# D2522AA register map
Vendor: Dialog; Series: D2522AA; File version: 1.2
CPU: CM0 r1p0, little endian, MPU, FPU, 3 interrupt priority bits
Registers are 32-bit, read-write, reset 0x0 unless marked. A register's access mark holds for its fields unless they carry their own. Offsets are from the block's base; [hi:lo] are bit positions; <NAME> marks a mode.

## CRG_XTAL — CRG_XTAL registers
Base 0x50010000
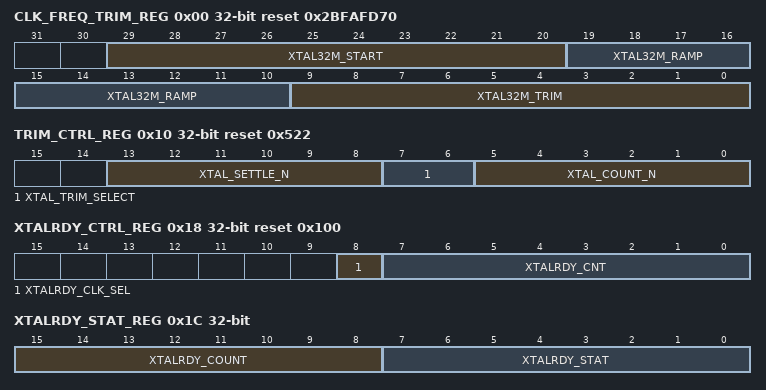
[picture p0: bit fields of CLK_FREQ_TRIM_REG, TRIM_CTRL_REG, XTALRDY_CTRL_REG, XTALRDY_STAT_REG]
0x00 CLK_FREQ_TRIM_REG reset 0x2BFAFD70 — Xtal frequency trimming register.
  [29:20] XTAL32M_START — Xtal frequency trimming register - START phase of startup 0x2BF = lowest frequency (high load capacitance) 0x000 = highest frequency (low load capacitance) Cload = 2.25p + 6.2p * XTAL32M_TRIM/0x2BF
  [19:10] XTAL32M_RAMP — Xtal frequency trimming register - RAMP phase of startup. 0x2BF = lowest frequency (high load capacitance) 0x000 = highest frequency (low load capacitance) Cload = 2.25p + 6.2p * XTAL32M_TRIM/0x2BF
  [9:0] XTAL32M_TRIM — Xtal frequency trimming register. 0x2BF = lowest frequency (high load capacitance) 0x000 = highest frequency (low load capacitance) Cload = 2.25p + 6.2p * XTAL32M_TRIM/0x2BF
0x0C XTAL32M_TRSTAT_REG — Read back value of current XTAL trimming
  [14:0] XTAL32M_TRSTAT ro — Reads value of the current XTAL trimming
0x10 TRIM_CTRL_REG reset 0x522 — Control trimming of the XTAL32M
  [13:8] XTAL_SETTLE_N — Designates that the XTAL can be safely used as the CPU clock. When XTAL_CLK_CNT reases this value, the signal XTAL_SETTLE_READY will be set
  [7:6] XTAL_TRIM_SELECT — Select which source controls the XTAL trimming 0b00: xtal counter. Starts XTAL32M_START_REG, after COUNT_N * 32 xtal pulses trim is changed to CLK_FREQ_TRIM_REG. 0b01: xtal OK filter. Starts with XTAL32_START_REG, when xtal is ramping is changed to CLK_FREQ_TRIM_REG 0b10: statically forced off. Only uses CLK_FREQ_TRIM_REG. 0b11: xtal OK filter, 2 stage. Starts with XTAL32_START_REG switches to XTAL16M_RAMP_REG when sw1='1', and switches to CLK_FREQ_TRIM_REG when sw2='1'.
  [5:0] XTAL_COUNT_N — Defines the number of XTAL cycles to be counted, before the xtal trimming is applied, in steps of 32. 0x01: 32 0x02: 64 0x3f:2016
0x18 XTALRDY_CTRL_REG reset 0x100 — Control register for XTALRDY IRQ
  [8] XTALRDY_CLK_SEL — XTALRDY IRQ timer clock selection: 0: 32KHz 1: 256kHz
  [7:0] XTALRDY_CNT — Number of 32kHz or 256kHz cycles between the crystal is enabled, and the XTALRDY_IRQ is fired. Frequency set by XTALRDY_CLK_SEL. 0x00: no interrupt
0x1C XTALRDY_STAT_REG — Difference between XTAL_OK and XTALRDY_IRQ in LP clock cycles
  [15:8] XTALRDY_COUNT ro — Current value of IRQ counter
  [7:0] XTALRDY_STAT ro — Value of IRQ counter when trimming is switched from RAMP to TRIM
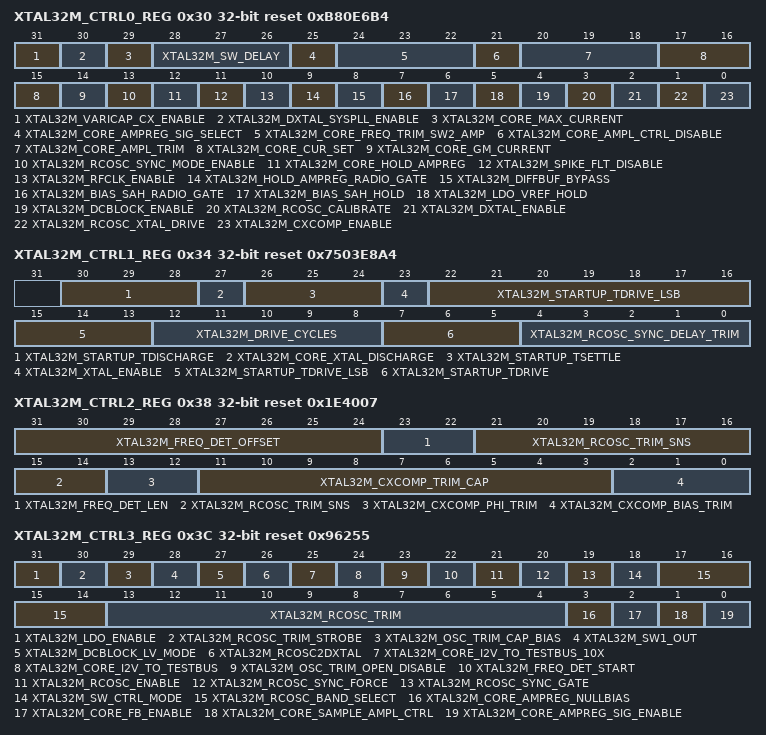
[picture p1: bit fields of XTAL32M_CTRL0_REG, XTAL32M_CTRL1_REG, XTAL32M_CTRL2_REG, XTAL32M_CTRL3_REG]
0x30 XTAL32M_CTRL0_REG reset 0xB80E6B4 (reset mask 0x7FFFFFFF) — Control register for XTAL32M
  [31] XTAL32M_VARICAP_CX_ENABLE — Enables shunt-cap compensation capacitance (OSF BOOST)
  [30] XTAL32M_DXTAL_SYSPLL_ENABLE — Enables DXTAL for the system PLL.
  [29] XTAL32M_CORE_MAX_CURRENT — Forces maximum current in output device.
  [28:26] XTAL32M_SW_DELAY — Set sw1 delay (sample output current comparator) and sw2 mask delay time. 0x0: 128 us 0x1: 64 us 0x2: 32 us 0x3: 16 us 0x4: 8 us 0x5: 4 us 0x6: 2 us 0x7: 1 us
  [25] XTAL32M_CORE_AMPREG_SIG_SELECT — 1: Select xtal_n for amplitude control. 0: Select xtal_p for amplitude control.
  [24:22] XTAL32M_CORE_FREQ_TRIM_SW2_AMP — Set threshold for amplitude control ok detection. 0x0: Highest current delta 0x6: Lowest current delta 0x7: off
  [21] XTAL32M_CORE_AMPL_CTRL_DISABLE — Disable amplitude-control block.
  [20:18] XTAL32M_CORE_AMPL_TRIM — Core amplitude trim setting. 0x0: min amplitude ... ... 0x5: max amplitude 0x6 & 0x7 are equal to 0x3.
  [17:15] XTAL32M_CORE_CUR_SET — Core current trim setting. 0x0: min current ... 0x3: default current ... 0x6 max amplitude 0x7 is equal to 0x3.
  [14] XTAL32M_CORE_GM_CURRENT — Enables biassing of the main oscillator output device
  [13] XTAL32M_RCOSC_SYNC_MODE_ENABLE — Enable synchronization of the crystal startup.
  [12] XTAL32M_CORE_HOLD_AMPREG — Put amplitude detector in HOLD mode.
  [11] XTAL32M_SPIKE_FLT_DISABLE — Disable DXTAL spike filter.
  [10] XTAL32M_RFCLK_ENABLE — If set, rfclk is allowed to be enabled
  [9] XTAL32M_HOLD_AMPREG_RADIO_GATE — Allow radio_enable to put amplitude detector in HOLD mode.
  [8] XTAL32M_DIFFBUF_BYPASS — Bypass comparator to use external input.
  [7] XTAL32M_BIAS_SAH_RADIO_GATE — Allow radio_enable to put the bias block in HOLD mode.
  [6] XTAL32M_BIAS_SAH_HOLD — Put the bias block in HOLD mode.
  [5] XTAL32M_LDO_VREF_HOLD — Put the LDO in HOLD mode.
  [4] XTAL32M_DCBLOCK_ENABLE — Eable dcblock circuit.
  [3] XTAL32M_RCOSC_CALIBRATE — Request an RC-oscillator calibration. If set, calibration will be started after xtal startup.
  [2] XTAL32M_DXTAL_ENABLE — Enable DXTAL - signal is gated by state-machine. Bit should always be set.
  [1] XTAL32M_RCOSC_XTAL_DRIVE — Enable drive of crystal by RCOSC, needed for fast startup
  [0] XTAL32M_CXCOMP_ENABLE — Enable the shunt-capacitance compensation amplifier circuit (OSF BOOST).
0x34 XTAL32M_CTRL1_REG reset 0x7503E8A4 — Control register for XTAL32M
  [30:28] XTAL32M_STARTUP_TDISCHARGE — Discharge time. 0x0: disable 0x1: 8 us 0x2: 4 us 0x3: 2 us 0x4: 1 us 0x5: 1/2 us 0x6: 1/8 us 0x7: 1/32 us
  [27] XTAL32M_CORE_XTAL_DISCHARGE — Software control mode: discharges the crystal.
  [26:24] XTAL32M_STARTUP_TSETTLE — Settle time. 0x0: 16 us 0x1: 8 us 0x2: 4 us 0x3: 2 us 0x4: 1 us 0x5: 1/2 us 0x6: 1/4 us 0x7: 1/8 us
  [23] XTAL32M_XTAL_ENABLE — Enable xtal (startup) or enable xtal block (software control mode) - testing only, to enable xtal, use PDC.
  [22:13] XTAL32M_STARTUP_TDRIVE_LSB — LSB part of the sequence drive time. From 0 to 32us with steps of 1/32us.
  [12:8] XTAL32M_DRIVE_CYCLES — Number of sequences to drive at startup.
  [7:5] XTAL32M_STARTUP_TDRIVE — Drive time of the sequence. 0x0: 32 us 0x1: 16 us 0x2: 8 us 0x3: 4 us 0x4: 2 us 0x5: 1 us 0x6: 1/2 us 0x7: 1/4 us
  [4:0] XTAL32M_RCOSC_SYNC_DELAY_TRIM — Synchronization mode delay trim..
0x38 XTAL32M_CTRL2_REG reset 0x1E4007 (reset mask 0x7FFFFFFF) — Control register for XTAL32M
  [31:24] XTAL32M_FREQ_DET_OFFSET — Add extra offset to the frequency-detector result to compensate for mismatch between actual startup and frequency-detector result.
  [23:22] XTAL32M_FREQ_DET_LEN — Length of frequency detection, used during calibration of the RC-oscillator. 0x0 :256us M=8k 0x1: 128us M=4k 0x2: 64us M=2k 0x3: 32us M=1k
  [21:14] XTAL32M_RCOSC_TRIM_SNS — Trim sensitivity used during calibration of the RC-oscillator.set to 122*M/128
  [13:12] XTAL32M_CXCOMP_PHI_TRIM — Phase correction for cxcomp circuit.
  [11:3] XTAL32M_CXCOMP_TRIM_CAP — Size of shunt capacitance compensation cap
  [2:0] XTAL32M_CXCOMP_BIAS_TRIM — Bias current of the cxcomp circuit. 0x0: minimum current (disabled) ... 0x7: maximum current
0x3C XTAL32M_CTRL3_REG reset 0x96255 (reset mask 0x7FFFFFFF) — Control register for XTAL32M
  [31] XTAL32M_LDO_ENABLE — Force enable LDO.
  [30] XTAL32M_RCOSC_TRIM_STROBE — Force RC-oscillator trim setting.
  [29] XTAL32M_OSC_TRIM_CAP_BIAS — 0: Connect varicap bottom-plate to top-plate with resistor. 1: Connect varicap bottom-plate to fixed bias voltage.
  [28] XTAL32M_SW1_OUT — Software control mode: force SW1 signal (xtaltrim delay between RAMP and START)
  [27] XTAL32M_DCBLOCK_LV_MODE — Low-voltage cmp testmode.
  [26] XTAL32M_RCOSC2DXTAL — Use RC-oscillator output for DXTAL.
  [25] XTAL32M_CORE_I2V_TO_TESTBUS_10X — Increase the gain of the core amplifier testmode.
  [24] XTAL32M_CORE_I2V_TO_TESTBUS — Enable the core amplifier testmode.
  [23] XTAL32M_OSC_TRIM_OPEN_DISABLE — Varicap testmode, feedback resistors are disabled.
  [22] XTAL32M_FREQ_DET_START — Force start frequency detector.
  [21] XTAL32M_RCOSC_ENABLE — Force Enable RC-oscillator
  [20] XTAL32M_RCOSC_SYNC_FORCE — Force a the RCOSC synchronization: driver startst.
  [19] XTAL32M_RCOSC_SYNC_GATE — Gate the RC-oscillator (and driver), when signal falls, the RC-oscillator will startup synchronized.
  [18] XTAL32M_SW_CTRL_MODE — Enable all the software overrides, the state-machine will remain in IDLE.
  [17:14] XTAL32M_RCOSC_BAND_SELECT — Set RCOSC band select - apply with RCOSC_TRIM_STROBE
  [13:4] XTAL32M_RCOSC_TRIM — Set RCOSC trim (fine) - apply with RCOSC_TRIM_STROBE
  [3] XTAL32M_CORE_AMPREG_NULLBIAS — Keep bias in ampdet alive, even when there is a large drive.
  [2] XTAL32M_CORE_FB_ENABLE — Enable feedback resistors on core amplifier output.
  [1] XTAL32M_CORE_SAMPLE_AMPL_CTRL — Software control mode: Sample voltage on amplitude detector.
  [0] XTAL32M_CORE_AMPREG_SIG_ENABLE — Software override to enable amplitude detector input signal.
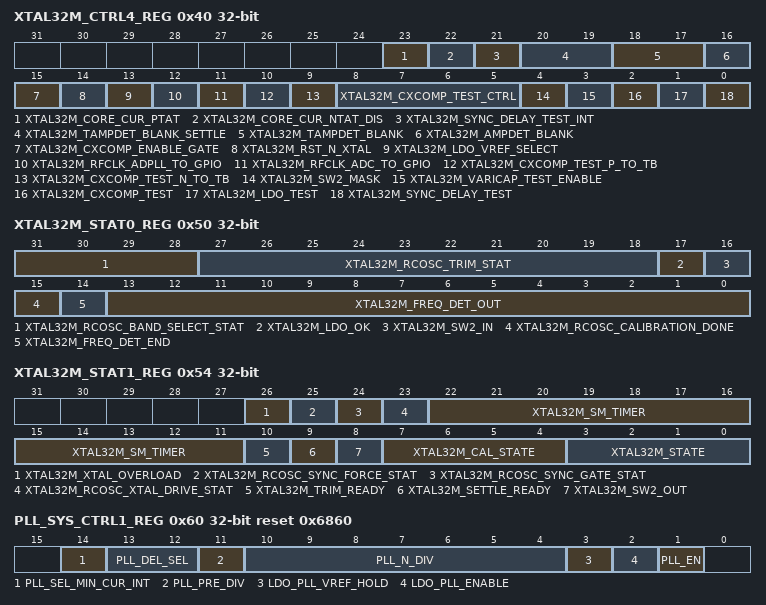
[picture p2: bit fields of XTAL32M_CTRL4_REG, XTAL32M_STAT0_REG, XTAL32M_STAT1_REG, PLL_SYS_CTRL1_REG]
0x40 XTAL32M_CTRL4_REG — Control register for XTAL32M
  [23] XTAL32M_CORE_CUR_PTAT — Adds PTAT current contribution to the ampltude regulator (TEST ONLY)
  [22] XTAL32M_CORE_CUR_NTAT_DIS — Disables the (NTAT) current contribution in the ampltidue regulator
  [21] XTAL32M_SYNC_DELAY_TEST_INT — When in SYNC_DELAY_TESTMODE, use RCOSC output instead of DXTAL. This allows for the xtal pins not to be in the delay-loop (ATE test)
  [20:19] XTAL32M_TAMPDET_BLANK_SETTLE — Amplitude regulator settling time - allows for amplitude regulator to settle to its value when drive sequence is completed.
  [18:17] XTAL32M_TAMPDET_BLANK — Blanking time for amplitude regulator when GM_CURRENT is set by state-machine
  [16] XTAL32M_AMPDET_BLANK — Enable blaning of the amplitude regulator - blanks glitch from the enabling of GM_CURRENT
  [15] XTAL32M_CXCOMP_ENABLE_GATE — Use CXCOMP circuit only at startup. Enable signal of CXCOMP circuit is gated with trim_ready signal.
  [14] XTAL32M_RST_N_XTAL — Software control mode - releases reset of control logic in xtal
  [13] XTAL32M_LDO_VREF_SELECT — 0: Select 1.2V reference input for the LDO. 1: Select vref2 as reference input for the LDO.
  [12] XTAL32M_RFCLK_ADPLL_TO_GPIO — Enable test output of rfclk_adpll to GPIO
  [11] XTAL32M_RFCLK_ADC_TO_GPIO — Enable test output of rfclk_adc to GPIO
  [10] XTAL32M_CXCOMP_TEST_P_TO_TB — Shuntcap measurement testmode: Put xtal_p on testbus<0>.
  [9] XTAL32M_CXCOMP_TEST_N_TO_TB — Shuntcap measurement testmode: Put xtal_n on testbus<0>.
  [8:5] XTAL32M_CXCOMP_TEST_CTRL — Shuntcap measurement testmode: Control cxcomp test switches. Bit 0: x_lo - discharge nodes Bit 1: p_hi - charge xtal_p to 1.2V Bit 2: n_hi - charge xtal_n to 1.2V Bit 3: cx_hi - charge CX node to 1.2V
  [4] XTAL32M_SW2_MASK — Software control mode: mask signal for sw2 (amplitude comparator output)
  [3] XTAL32M_VARICAP_TEST_ENABLE — Enable varicap test outputs to DCORE.
  [2] XTAL32M_CXCOMP_TEST — Enable the testmode of the cxcomp circuit.
  [1] XTAL32M_LDO_TEST — Put the LDO output voltage on testbus<0>.
  [0] XTAL32M_SYNC_DELAY_TEST — Enable the calibration/testmode of the sync circuit.
0x50 XTAL32M_STAT0_REG (reset mask 0x7FFFFFFF) — Status register for XTAL32M
  [31:28] XTAL32M_RCOSC_BAND_SELECT_STAT ro — Currently selected band.
  [27:18] XTAL32M_RCOSC_TRIM_STAT ro — Current trim result.
  [17] XTAL32M_LDO_OK ro — XTAL32M LDO output voltage is: 0: not OK, 1: OK
  [16] XTAL32M_SW2_IN ro — Amplitude comparator output signal.
  [15] XTAL32M_RCOSC_CALIBRATION_DONE ro — Signals that the calibration phase has been completed.
  [14] XTAL32M_FREQ_DET_END ro — Signals that frequency detection has been completed.
  [13:0] XTAL32M_FREQ_DET_OUT ro — Result of frequency detection.
0x54 XTAL32M_STAT1_REG — Status register for XTAL32M
  [26] XTAL32M_XTAL_OVERLOAD ro — Indicates xtal is (heavily) overloaded
  [25] XTAL32M_RCOSC_SYNC_FORCE_STAT ro — Value of the synchronization force signal from the calibration or startup state-machine.
  [24] XTAL32M_RCOSC_SYNC_GATE_STAT ro — Value of the gate force signal from the calibration and startup state-machine.
  [23] XTAL32M_RCOSC_XTAL_DRIVE_STAT ro — Value of the XTAL drive signal from the startup state-machine.
  [22:11] XTAL32M_SM_TIMER ro — Current value of the counter used for various timeouts.
  [10] XTAL32M_TRIM_READY ro — Signals that the crystal-oscillator trimming has been completed.
  [9] XTAL32M_SETTLE_READY ro — Signals that the crystal has been settled.
  [8] XTAL32M_SW2_OUT ro — Masked sw2_in signal.
  [7:4] XTAL32M_CAL_STATE ro — Current state of the calibration state-machine. 0x0: CAL_DELAY - Delay for the biasing to settle 0x1: CAL_SYNC - Enables synchronization circuit 0x2: CAL_FREQDET - Enables the frequency detector 0x3: CAL_OFFSET - Evaluate OFFSET trimresult 0x4: CAL_MULT_SHIFT - Evaluate (delta) trimresult 0x5: CAL_TRIM - Generate new trimvalue 0x6: CAL_BAND_UPDWN - Delay after band change 0x7: CAL_END - Calibration ended 0x8: CAL_IDLE - Calibration IDLE (default state)
  [3:0] XTAL32M_STATE ro — Current state of the startup state-machine. 0x0: XTAL_WAIT_LDO - Allow for setling of the biasing 0x1: XTAL_DRIVE - Crystal is driven by rcosc 0x2: XTAL_DISCHARGE - Discharge loadcaps 0x3: XTAL_SETTLE - Allows for settling of the xtal signal 0x4: XTAL_SYNC - Restart RCOSC, and synchronize 0x5: XTAL_OVERLOAD_DETECT - amplitude detection mode by overload bit 0x6: XTAL_OVERLOAD_BLANK_SETTLE - setling delay for amplitude regulator when drive ends 0x7: XTAL_OVERLOAD_BLANK - blank glitch from enabling gm_current 0x8: XTAL_RUN - Startup ended 0x9: XTAL_SAMPLE - Delay before sample amplitude control 0xa: XTAL_SW2_MASK - Delay for masked SW2 0xb: XTAL_IDLE - Idle state (default)
0x60 PLL_SYS_CTRL1_REG reset 0x6860 — System PLL control register 1.
  [14] PLL_SEL_MIN_CUR_INT — 0: VCO current read from min_current <5:0>, 1: VCO current is internally determined with a calibration algoritm.
  [13:12] PLL_DEL_SEL — PLL manual delay value for Phase Frequency Detector. 0: 0.493 1: 0.814 2: 1.13 ns <- default 3: 1.44 ns
  [11] PLL_PRE_DIV — PLL input divider (1: Indicates divide by 2).
  [10:4] PLL_N_DIV — PLL loop divider N (x means divide by x, 0 means divide by 1)
  [3] LDO_PLL_VREF_HOLD — 0: Indicates that the reference input is tracked, 1: Indicates that the reference input is sampled.
  [2] LDO_PLL_ENABLE — 0: LDO PLL off, 1: LDO PLL on.
  [1] PLL_EN — 0: Power down 1: PLL on
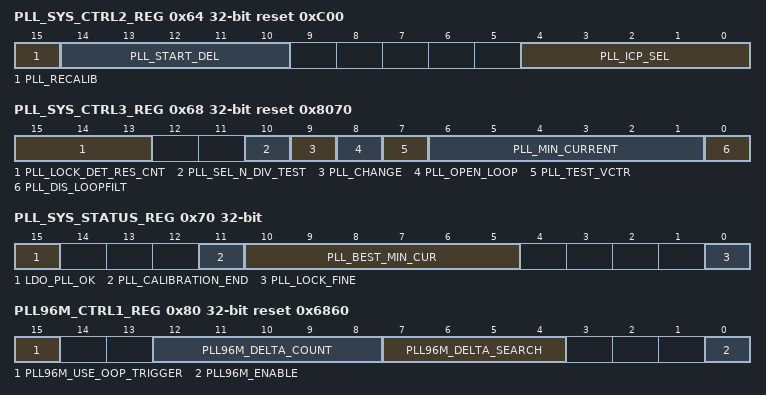
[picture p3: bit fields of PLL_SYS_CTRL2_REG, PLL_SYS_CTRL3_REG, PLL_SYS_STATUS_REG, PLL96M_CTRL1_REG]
0x64 PLL_SYS_CTRL2_REG reset 0xC00 — System PLL control register 2.
  [15] PLL_RECALIB — Recalibrate
  [14:10] PLL_START_DEL — Programmable delay time for the loop filter voltage preset value. After PLL_EN is set, the loopfilter precharge resistors are disabled after this delay time. One LSB is 48 ns
  [4:0] PLL_ICP_SEL — PLL charge pump current select One LSB is 5uA.
0x68 PLL_SYS_CTRL3_REG reset 0x8070 — System PLL control register 3.
  [15:13] PLL_LOCK_DET_RES_CNT — Lock measurement time in <tbd> clock cycle of xx usec. After this period PLL_LOCK_FINE is calculated based on the difference of the M and N counted pulses in that period. If PLL_LOCK_FINE is still 0, the lock state machine restarts until PLL_LOCK_FINE gets 1 0: <tbd> usec 7: <tbd> usec
  [10] PLL_SEL_N_DIV_TEST — Select test mode for loop divider N. Maps PLL_N_DIV input on pins <tbd> and divider output on pin <tbd>
  [9] PLL_CHANGE — 0: normal value 1: reverse charge pump up/down signals
  [8] PLL_OPEN_LOOP — 1: set to open loop to termine max frequency
  [7] PLL_TEST_VCTR — 1: map loopfilter voltage on external pin <tbd>
  [6:1] PLL_MIN_CURRENT — VCO current trimming.
  [0] PLL_DIS_LOOPFILT — 1: disable PLL internal loop filter
0x70 PLL_SYS_STATUS_REG — System PLL status register.
  [15] LDO_PLL_OK ro — 1: Indicates that LDO PLL is in regulation.
  [11] PLL_CALIBRATION_END ro — Indicates that calibration has finished.
  [10:5] PLL_BEST_MIN_CUR ro — Calibrated VCO current.
  [0] PLL_LOCK_FINE ro — 1: PLL locked
0x80 PLL96M_CTRL1_REG reset 0x6860 — System PLL control register 2
  [15] PLL96M_USE_OOP_TRIGGER — Prevents an out-of-phase trigger in case the DCO runs too slow or too fast. Default: 0
  [12:8] PLL96M_DELTA_COUNT — Affects settling during a DCO "too_slow" or "too_fast" event. Default: 8
  [7:4] PLL96M_DELTA_SEARCH — Affects settling during a DCO "too_slow" or "too_fast" event. Default: 4
  [0] PLL96M_ENABLE — 0: Power down 1: PLL on
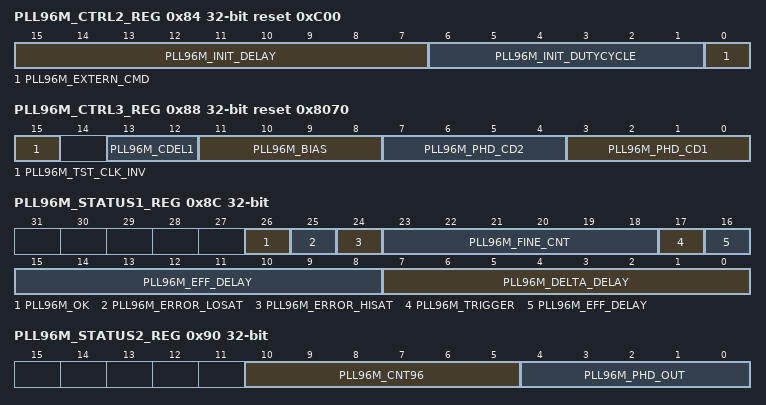
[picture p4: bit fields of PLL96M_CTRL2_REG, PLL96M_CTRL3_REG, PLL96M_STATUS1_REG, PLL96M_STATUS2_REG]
0x84 PLL96M_CTRL2_REG reset 0xC00 — System PLL control register 1
  [15:7] PLL96M_INIT_DELAY — Initial delay of the DCO timer. 0: minimum 223: default 447: maximum
  [6:1] PLL96M_INIT_DUTYCYCLE — Initial duty-cycle adjustment value. 0: 42.5% 32: 50% 63: 57.5%)
  [0] PLL96M_EXTERN_CMD — 0: Normal operation, 1: Override DCO delay with PL96M_INIT_DELAY
0x88 PLL96M_CTRL3_REG reset 0x8070 — System PLL control register 3
  [15] PLL96M_TST_CLK_INV — Invert test data clock polarity. Default: 0
  [13:12] PLL96M_CDEL1 — Phase-detector digital delay correction. Default: 3
  [11:8] PLL96M_BIAS — Bias adjustment. Default: 8
  [7:4] PLL96M_PHD_CD2 — Phase-detector delay coefficient 2. Default: 8
  [3:0] PLL96M_PHD_CD1 — Phase-detector delay coefficient 1. Default: 5
0x8C PLL96M_STATUS1_REG — System PLL status register 1
  [26] PLL96M_OK ro — 1: The PLL is producing a valid 96MHz output clock.
  [25] PLL96M_ERROR_LOSAT ro — 1: PLL out-of-range: low saturation error
  [24] PLL96M_ERROR_HISAT ro — 1: PLL out-of-range: high saturation error
  [23:18] PLL96M_FINE_CNT ro — Counts subsequent cycles that the controller is in fine-adjust algorithm (high number predicts low jitter)
  [17] PLL96M_TRIGGER ro — Trigger output that can restart the RC oscillator
  [16:8] PLL96M_EFF_DELAY ro — Effective delay value
  [7:0] PLL96M_DELTA_DELAY ro — Delta delay correction value
0x90 PLL96M_STATUS2_REG — System PLL status register 2
  [10:5] PLL96M_CNT96 ro — Number of internal oscillator pulses within 4 periods of the reference clock (should be 12)
  [4:0] PLL96M_PHD_OUT ro — Phase-detector output vector. 0x00: UP3 - Clock is too slow 0x01: UP2 0x03: UP1 0x07: DN1 0x0F: DN2 0x1F: DN3 - Clock is too fast
